# ATSAMR21E18A register map
Vendor: Microchip Technology Inc.; Series: SAMR21; File version: D
CPU: CM0+ r0p1, little endian, no MPU, no FPU, VTOR, 2 interrupt priority bits, 28 interrupts
Registers are 8-bit, read-write, reset 0x0 unless marked. A register's access mark holds for its fields unless they carry their own. Offsets are from the block's base; [hi:lo] are bit positions; {n}, {i} and the like mark numbered series; 'fields as' and 'values as' point back to an identical list.

## GCLK — Generic Clock Generator
Base 0x40000C00; register names take the prefix GCLK_
0x00 CTRL — Control
  [0] SWRST — Software Reset
0x01 STATUS ro
  [7] SYNCBUSY — Synchronization Busy Status
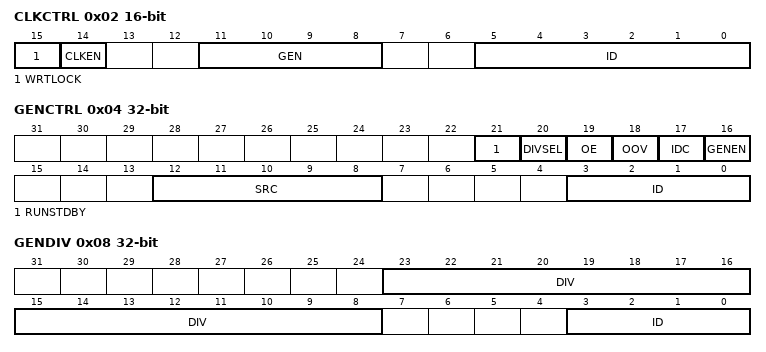
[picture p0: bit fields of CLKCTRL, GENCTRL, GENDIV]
0x02 CLKCTRL 16-bit — Generic Clock Control
  [15] WRTLOCK — Write Lock
  [14] CLKEN — Clock Enable
  [11:8] GEN — Generic Clock Generator
    {v}=GCLK{v} (Generic clock generator {v}) (v=0..8)
  [5:0] ID — Generic Clock Selection ID
    0=DFLL48; 1=FDPLL; 2=FDPLL32K; 3=WDT; 4=RTC; 5=EIC; 6=USB; {v}=EVSYS_{v-7} (v=7..18); 19=SERCOMX_SLOW; {v}=SERCOM{v-20}_CORE (v=20..25); 26=TCC0_TCC1; 27=TCC2_TC3; 28=TC4_TC5; 29=TC6_TC7; 30=ADC; 31=AC_DIG; 32=AC_ANA; 33=DAC; 35=I2S_0; 36=I2S_1
0x04 GENCTRL 32-bit — Generic Clock Generator Control
  [21] RUNSTDBY — Run in Standby
  [20] DIVSEL — Divide Selection
  [19] OE — Output Enable
  [18] OOV — Output Off Value
  [17] IDC — Improve Duty Cycle
  [16] GENEN — Generic Clock Generator Enable
  [12:8] SRC — Source Select
    0=XOSC (XOSC oscillator output); 1=GCLKIN (Generator input pad); 2=GCLKGEN1 (Generic clock generator 1 output); 3=OSCULP32K (OSCULP32K oscillator output); 4=OSC32K (OSC32K oscillator output); 5=XOSC32K (XOSC32K oscillator output); 6=OSC8M (OSC8M oscillator output); 7=DFLL48M (DFLL48M output); 8=DPLL96M (DPLL96M output)
  [3:0] ID — Generic Clock Generator Selection
0x08 GENDIV 32-bit — Generic Clock Generator Division
  [23:8] DIV — Division Factor
  [3:0] ID — Generic Clock Generator Selection

## HMATRIX — HSB Matrix
Base 0x41007000; register names take the prefix HMATRIXB_
{0x80+8i} PRAS{i} (i=0..15) 32-bit — Priority A for Slave
{0x84+8i} PRBS{i} (i=0..15) 32-bit — Priority B for Slave
{0x110+4i} SFR{i} (i=0..15) 32-bit — Special Function
  [31:0] SFR — Special Function Register

## MTB — Cortex-M0+ Micro-Trace Buffer
Base 0x41006000; register names take the prefix MTB_
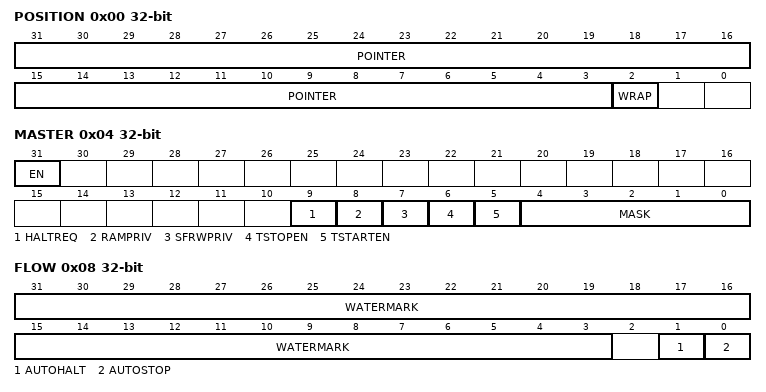
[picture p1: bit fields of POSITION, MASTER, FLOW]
0x00 POSITION 32-bit — MTB Position
  [31:3] POINTER — Trace Packet Location Pointer
  [2] WRAP — Pointer Value Wraps
0x04 MASTER 32-bit — MTB Master
  [31] EN — Main Trace Enable
  [9] HALTREQ — Halt Request
  [8] RAMPRIV — SRAM Privilege
  [7] SFRWPRIV — Special Function Register Write Privilege
  [6] TSTOPEN — Trace Stop Input Enable
  [5] TSTARTEN — Trace Start Input Enable
  [4:0] MASK — Maximum Value of the Trace Buffer in SRAM
0x08 FLOW 32-bit — MTB Flow
  [31:3] WATERMARK — Watermark value
  [1] AUTOHALT — Auto Halt Request
  [0] AUTOSTOP — Auto Stop Tracing
0x0C BASE 32-bit ro — MTB Base
0xF00 ITCTRL 32-bit — MTB Integration Mode Control
0xFA0 CLAIMSET 32-bit — MTB Claim Set
0xFA4 CLAIMCLR 32-bit — MTB Claim Clear
0xFB0 LOCKACCESS 32-bit — MTB Lock Access
0xFB4 LOCKSTATUS 32-bit ro — MTB Lock Status
0xFB8 AUTHSTATUS 32-bit ro — MTB Authentication Status
0xFBC DEVARCH 32-bit ro — MTB Device Architecture
0xFC8 DEVID 32-bit ro — MTB Device Configuration
0xFCC DEVTYPE 32-bit ro — MTB Device Type
{0xFC0+4i} PID{i} 32-bit ro (i=4..7) — CoreSight
{0xFE0+4i} PID{i} 32-bit ro (i=0..3) — CoreSight
{0xFF0+4i} CID{i} 32-bit ro (i=0..3) — CoreSight

## NVMCTRL — Non-Volatile Memory Controller
Base 0x41004000; register names take the prefix NVMCTRL_
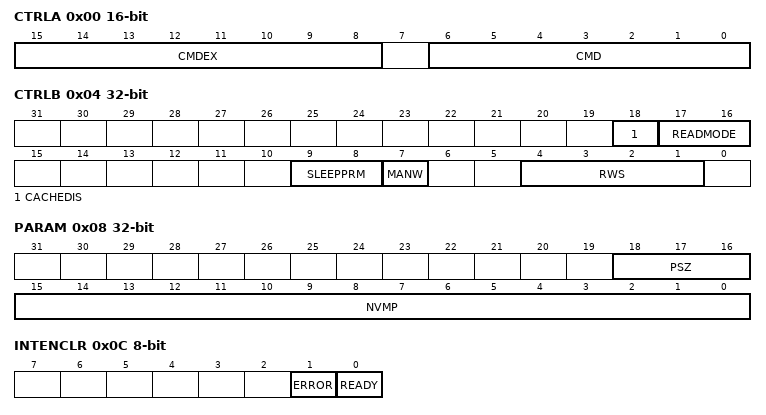
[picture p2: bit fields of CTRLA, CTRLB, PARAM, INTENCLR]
0x00 CTRLA 16-bit — Control A
  [15:8] CMDEX — Command Execution
    165=KEY (Execution Key)
  [6:0] CMD — Command
    2=ER (Erase Row - Erases the row addressed by the ADDR register.); 4=WP (Write Page - Writes the contents of the page buffer to the page addressed by the ADDR register.); 5=EAR (Erase Auxiliary Row - Erases the auxiliary row addressed by the ADDR register. This command can be given only when the security bit is not set and only to the user configuration row.); 6=WAP (Write Auxiliary Page - Writes the contents of the page buffer to the page addressed by the ADDR register. This command can be given only when the security bit is not set and only to the user configuration row.); 10=SF (Security Flow Command); 15=WL (Write lockbits); 64=LR (Lock Region - Locks the region containing the address location in the ADDR register.); 65=UR (Unlock Region - Unlocks the region containing the address location in the ADDR register.); 66=SPRM (Sets the power reduction mode.); 67=CPRM (Clears the power reduction mode.); 68=PBC (Page Buffer Clear - Clears the page buffer.); 69=SSB (Set Security Bit - Sets the security bit by writing 0x00 to the first byte in the lockbit row.); 70=INVALL (Invalidates all cache lines.)
0x04 CTRLB 32-bit — Control B
  [18] CACHEDIS — Cache Disable
  [17:16] READMODE — NVMCTRL Read Mode
    0=NO_MISS_PENALTY (The NVM Controller (cache system) does not insert wait states on a cache miss. Gives the best system performance.); 1=LOW_POWER (Reduces power consumption of the cache system, but inserts a wait state each time there is a cache miss. This mode may not be relevant if CPU performance is required, as the application will be stalled and may lead to increase run time.); 2=DETERMINISTIC (The cache system ensures that a cache hit or miss takes the same amount of time, determined by the number of programmed flash wait states. This mode can be used for real-time applications that require deterministic execution timings.)
  [9:8] SLEEPPRM — Power Reduction Mode during Sleep
    0=WAKEONACCESS (NVM block enters low-power mode when entering sleep.NVM block exits low-power mode upon first access.); 1=WAKEUPINSTANT (NVM block enters low-power mode when entering sleep.NVM block exits low-power mode when exiting sleep.); 3=DISABLED (Auto power reduction disabled.)
  [7] MANW — Manual Write
  [4:1] RWS — NVM Read Wait States
    0=SINGLE (Single Auto Wait State); 1=HALF (Half Auto Wait State); 2=DUAL (Dual Auto Wait State)
0x08 PARAM 32-bit — NVM Parameter
  [18:16] PSZ ro — Page Size
    0=8 bytes; 1=16 bytes; 2=32 bytes; 3=64 bytes; 4=128 bytes; 5=256 bytes; 6=512 bytes; 7=1024 bytes
  [15:0] NVMP ro — NVM Pages
0x0C INTENCLR — Interrupt Enable Clear
  [1] ERROR — Error Interrupt Enable
  [0] READY — NVM Ready Interrupt Enable
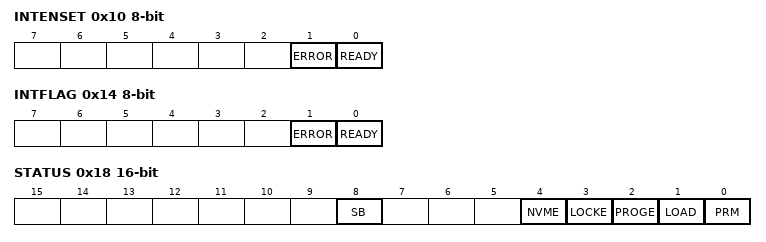
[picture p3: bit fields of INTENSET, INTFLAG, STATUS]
0x10 INTENSET — Interrupt Enable Set
  fields as INTENCLR
0x14 INTFLAG — Interrupt Flag Status and Clear
  [1] ERROR
  [0] READY ro — NVM Ready
0x18 STATUS 16-bit
  [8] SB ro — Security Bit Status
  [4] NVME — NVM Error
  [3] LOCKE — Lock Error Status
  [2] PROGE — Programming Error Status
  [1] LOAD — NVM Page Buffer Active Loading
  [0] PRM ro — Power Reduction Mode
0x1C ADDR 32-bit — Address
  [21:0] ADDR — NVM Address
0x20 LOCK 16-bit — Lock Section
  [15:0] LOCK ro — Region Lock Bits

## Notices in the file
Copyright (c) 2018 Microchip Technology Inc.
SPDX-License-Identifier: Apache-2.0
Licensed under the Apache License, Version 2.0 (the "License");
you may not use this file except in compliance with the License.
You may obtain a copy of the License at
http://www.apache.org/licenses/LICENSE-2.0
Unless required by applicable law or agreed to in writing, software
distributed under the License is distributed on an "AS IS" BASIS,
WITHOUT WARRANTIES OR CONDITIONS OF ANY KIND, either express or implied.
See the License for the specific language governing permissions and
limitations under the License.
